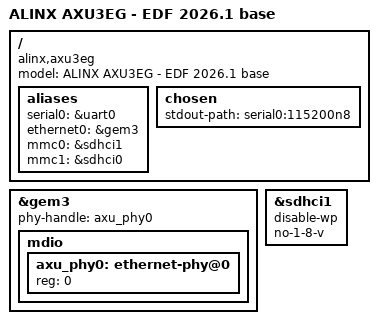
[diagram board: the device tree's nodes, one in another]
/ {
    model = "ALINX AXU3EG - EDF 2026.1 base";
    compatible = "alinx,axu3eg", "xlnx,zynqmp";
    aliases {
        serial0 = &uart0;
        ethernet0 = &gem3;
        mmc0 = &sdhci1;
        mmc1 = &sdhci0;
    };
    chosen { stdout-path = "serial0:115200n8"; };
};
&gem3 {
    status = "okay";
    phy-handle = <&axu_phy0>;
    mdio {
        #address-cells = <1>;
        #size-cells = <0>;
        axu_phy0: ethernet-phy@0 { reg = <0>; };
    };
};
&sdhci1 {
    disable-wp;
    no-1-8-v;
};
